# ATA5702M322 device description
Architecture: AVR8; Family: megaAVR
Registers are 8-bit, access not given, no defined reset value unless marked. A register's access mark holds for its fields unless they carry their own. Offsets are from the block's base; [hi:lo] are bit positions.

## TIMER4
Instances: TIMER4 0x00
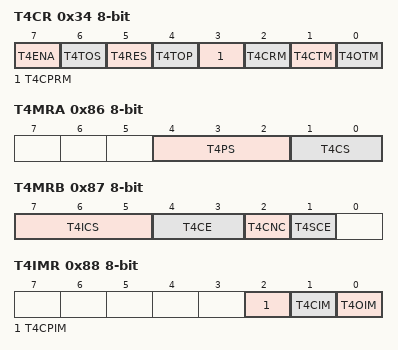
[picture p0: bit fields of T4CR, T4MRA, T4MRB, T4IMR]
0x34 T4CR — Timer4 control Register
  [7] T4ENA — Timer4 Enable
  [6] T4TOS — Timer4 Toggle with Start
  [5] T4RES — Timer4 Reset
  [4] T4TOP — Timer4 Toggle Output Preset
  [3] T4CPRM — Timer4 CaPture Reset Mask
  [2] T4CRM — Timer4 Compare Reset Mask
  [1] T4CTM — Timer4 Compare Toggle Mask
  [0] T4OTM — Timer4 Overflow Toggle Mask
0x80 T4CNT 16-bit — Timer4 counter Register
0x82 T4COR 16-bit — Timer4 compare Register
0x84 T4ICR 16-bit — Timer4 input capture Register
0x86 T4MRA — Timer4 mode Register
  [4:2] T4PS — Timer4 Prescaler Select
  [1:0] T4CS — Timer4 Clock Select
    0=clk_src; 1=clk_T; 2=clk_mrc; 3=clk_frc
0x87 T4MRB — Timer4 mode Register
  [7:5] T4ICS — Timer4 Input Capture Select
    0=clk_T2; 1=clk_T1; 2=clk_T3; 3=TICP; 4=LFES; 5=clk_src; 6=TPGAP
  [4:3] T4CE — Timer4 Capture Edge select
    0=disable; 1=rising edge; 2=falling edge; 3=both edges
  [2] T4CNC — Timer4 input Capture Noise Canceller
  [1] T4SCE — Timer4 Software Capture Enable
0x88 T4IMR — Timer4 interrupt mask Register
  [2] T4CPIM — Timer4 Capture Interrupt Mask
  [1] T4CIM — Timer4 Compare Interrupt Mask
  [0] T4OIM — Timer4 Overflow Interrupt Mask
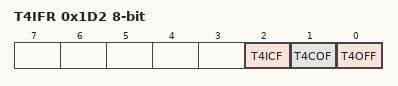
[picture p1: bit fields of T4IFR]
0x1D2 T4IFR — Timer4 interrupt flag Register
  [2] T4ICF — Timer4 Input Capture Flag
  [1] T4COF — Timer4 Compare Flag
  [0] T4OFF — Timer4 OverFlow Flag

## TIMER5
Instances: TIMER5 0x00
0x89 T5TEMP — Timer5 Temp Register
0x8A T5OCR 16-bit — Timer5 Output Compare Register
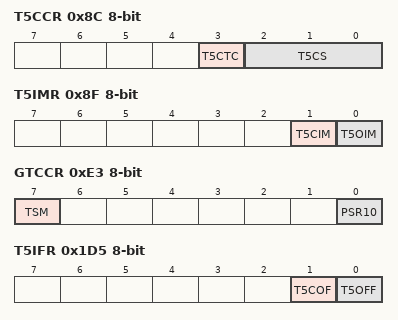
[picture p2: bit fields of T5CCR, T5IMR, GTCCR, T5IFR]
0x8C T5CCR — Timer5 Control Register
  [3] T5CTC — Clear Timer5 on Compare Match
  [2:0] T5CS — Timer5 Clock Select
    0=No Clock Source (Stopped); 1=Running, No Prescaling; 2=Running, CLK/8; 3=Running, CLK/32; 4=Running, CLK/64; 5=Running, CLK/128; 6=Running, CLK/256; 7=Running, CLK/1024
0x8D T5CNT 16-bit — Timer5 Counter
0x8F T5IMR — Timer5 Interrupt Mask Register
  [1] T5CIM — Timer5 Output Compare Interrupt Mask
  [0] T5OIM — Timer5 Output Overflow Interrupt Mask
0xE3 GTCCR — General Timer/Counter Control Register
  [7] TSM — Timer/Counter Synchronization Mode
  [0] PSR10 — PreScaler Reset
0x1D5 T5IFR — Timer5 Interrupt Flag Register
  [1] T5COF — Timer5 Output Compare Output Match Flag
  [0] T5OFF — Timer5 Output Overflow Flag

## TMO
Instances: TMO 0x00
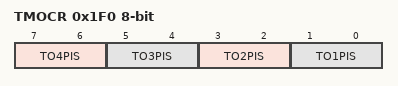
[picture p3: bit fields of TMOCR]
0x1F0 TMOCR — Timer Modulator Output Control Register
  [7:6] TO4PIS — Timer modulator Output 4 Port Interface Select
    0=Port D5 Data Register; 1=M1 - Toggle Register Timer1; 2=M2 - Toggle Register Timer2; 3=M3 - Toggle Register Timer3
  [5:4] TO3PIS — Timer modulator Output 3 Port Interface Select
    0=Port D4 Data Register; 1=M1 - Toggle Register Timer1; 2=M3 - Toggle Register Timer3; 3=M4 - Toggle Register Timer4
  [3:2] TO2PIS — Timer modulator Output 2 Port Interface Select
    0=Port D3 Data Register; 1=M1 - Toggle Register Timer1; 2=M2 - Toggle Register Timer2; 3=M4 - Toggle Register Timer4
  [1:0] TO1PIS — Timer modulator Output 1 Port Interface Select
    0=Port D2 Data Register; 1=M1 - Toggle Register Timer1; 2=M2 - Toggle Register Timer2; 3=M3 - Toggle Register Timer3

## TWI1
Instances: TWI1 0x00
0x1E9 TW1BR — TWI1 Bit Rate Register
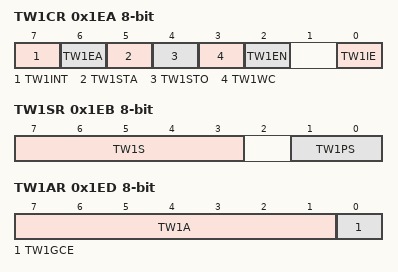
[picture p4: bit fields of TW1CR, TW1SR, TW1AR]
0x1EA TW1CR — TWI1 Control Register
  [7] TW1INT — TWI1 Interrupt Flag
  [6] TW1EA — TWI1 Enable Acknowledge
  [5] TW1STA — TWI1 START Condition
  [4] TW1STO — TWI1 STOP Condition
  [3] TW1WC — TWI1 Write Collision Flag
  [2] TW1EN — TWI1 Enable
  [0] TW1IE — TWI1 Interrupt Enable
0x1EB TW1SR — TWI1 Status Register
  [7:3] TW1S — TWI1 Status
  [1:0] TW1PS — TWI1 Prescaler
    0=1; 1=4; 2=16; 3=64
0x1EC TW1DR — TWI1 Data Register
0x1ED TW1AR — TWI1 (Slave) Address Register
  [7:1] TW1A — TWI1 (Slave) Address
  [0] TW1GCE — TWI1 General Call Recognition Enable
0x1EE TW1AMR — TWI1 Address Mask Register
  [7:1] TW1AM — TWI1 Address Mask
